# TC35678 register map
Vendor: Toshiba Electronic Devices and Storage Corporation; File version: 0.1
CPU: CM0 r0p0, little endian, no MPU, no FPU, 4 interrupt priority bits
Registers are 32-bit, read-write, no defined reset value unless marked. A register's access mark holds for its fields unless they carry their own. Offsets are from the block's base; [hi:lo] are bit positions; {n}, {i} and the like mark numbered series.

## DMAC
Base 0x40001000
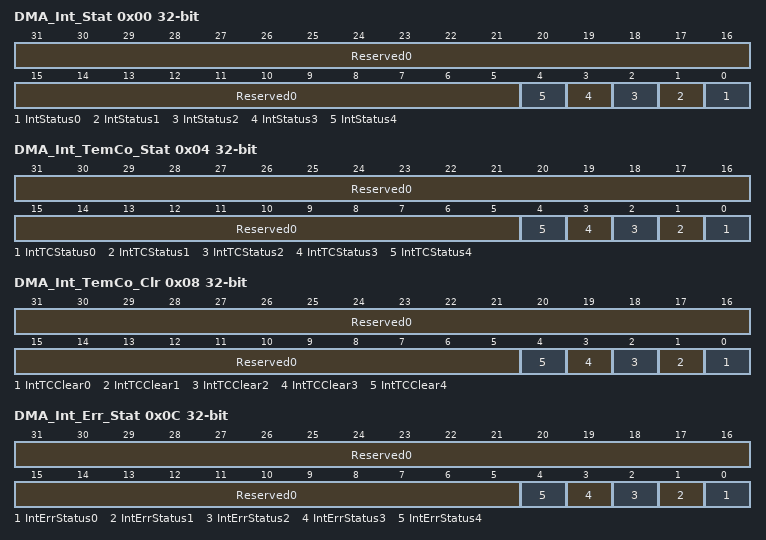
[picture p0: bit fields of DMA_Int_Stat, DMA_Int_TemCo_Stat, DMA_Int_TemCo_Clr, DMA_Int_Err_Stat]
0x00 DMA_Int_Stat ro — Interrupt Status Register
  [31:5] Reserved0 — Do not change the values.
  [n] IntStatus{n} (n=0..4) — DMAC ch{n} interrupt status. 0: No interrupt 1: Interrupt asserted. Both DMA error and DMA done assert this bit.
0x04 DMA_Int_TemCo_Stat ro — Interrupt Terminal Count Status Register
  [31:5] Reserved0 — Do not change the values.
  [n] IntTCStatus{n} (n=0..4) — DMAC ch{n} interrupt status of DMA done. 0: No interrupt 1: Interrupt asserted.
0x08 DMA_Int_TemCo_Clr — Interrupt Terminal Count Clear Register
  [31:5] Reserved0 — Do not change the values.
  [n] IntTCClear{n} ro (n=0..4) — Clear DMAC ch{n} DMA done interrupt. 0: Invalid 1: Clear
0x0C DMA_Int_Err_Stat ro — Interrupt Error Status Register
  [31:5] Reserved0 — Do not change the values.
  [n] IntErrStatus{n} (n=0..4) — DMAC ch{n} DMA error interrupt status 0: No interrupt 1: Interrupt asserted
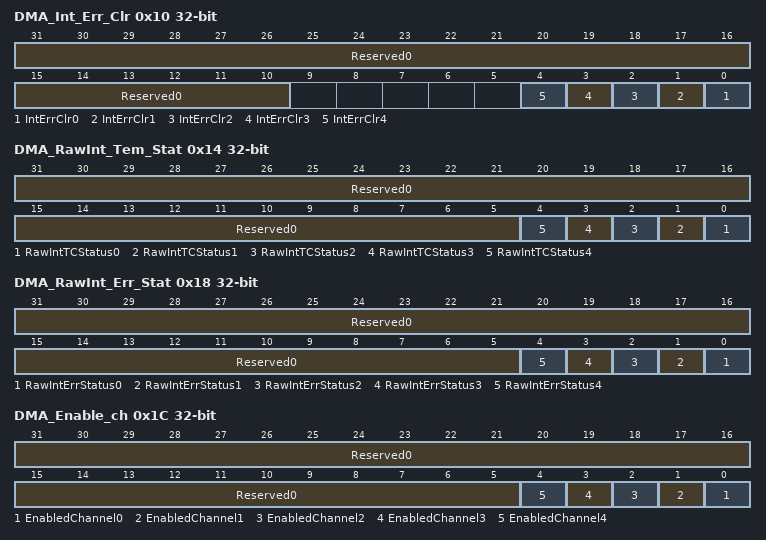
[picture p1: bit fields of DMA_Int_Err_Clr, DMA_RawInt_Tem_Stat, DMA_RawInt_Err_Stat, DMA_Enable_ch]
0x10 DMA_Int_Err_Clr — Interrupt Error Clear Register
  [31:10] Reserved0 — Do not change the values.
  [n] IntErrClr{n} (n=0..4) — Clear DMAC ch{n} DMA error interrupt 0: Invalid 1: Clear
0x14 DMA_RawInt_Tem_Stat ro — Raw Interrupt Terminal Count Status Register
  [31:5] Reserved0 — Do not change the values.
  [n] RawIntTCStatus{n} (n=0..4) — Unmasked DMAC ch{n} DMA done interrupt status 0: No interrupt 1: Interrupt asserted
0x18 DMA_RawInt_Err_Stat ro — Raw Interrupt Error Status Register
  [31:5] Reserved0 — Do not change the values.
  [n] RawIntErrStatus{n} (n=0..4) — Unmasked DMAC ch{n} DMA error interrupt status 0: No interrupt 1: Interrupt asserted
0x1C DMA_Enable_ch ro — Enabled Channel Register
  [31:5] Reserved0 — Do not change the values.
  [n] EnabledChannel{n} (n=0..4) — Enable/Disable DMAC ch{n} 0: Disable 1: Enable
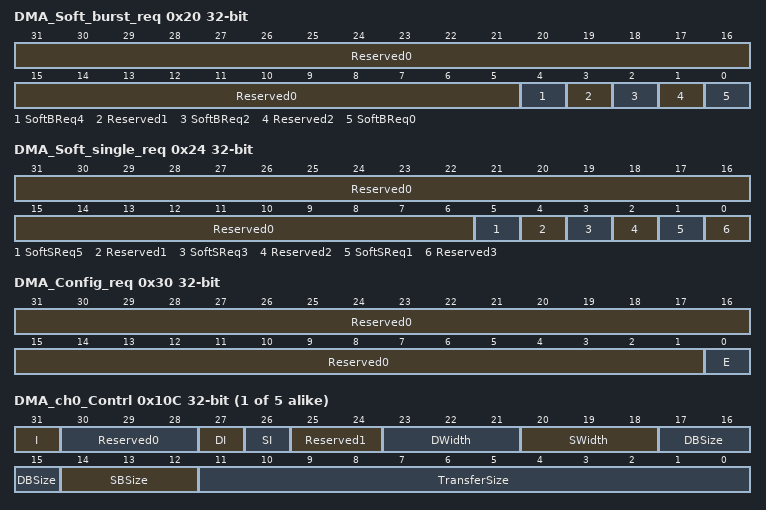
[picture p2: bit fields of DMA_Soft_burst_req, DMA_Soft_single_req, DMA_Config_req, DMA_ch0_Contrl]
0x20 DMA_Soft_burst_req — Software Burtst Request Register
  [31:5] Reserved0 — Do not change the values.
  [4] SoftBReq4 — Set DMA burst request for peripheral number 4 0: Invalid request 1: Occur request
  [3] Reserved1 — Do not change the values.
  [2] SoftBReq2 — Set DMA burst request for peripheral number 2 0: Invalid request 1: Occur request
  [1] Reserved2 — Do not change the values.
  [0] SoftBReq0 — Set DMA burst request for peripheral number 0 0: Invalid request 1: Occur request
0x24 DMA_Soft_single_req — Software Single Request Register
  [31:6] Reserved0 — Do not change the values.
  [5] SoftSReq5 — Set DMA single request for peripheral number 5 0: Invalid request 1: Occur request
  [4] Reserved1 — Do not change the values.
  [3] SoftSReq3 — Set DMA single request for peripheral number 3 0: Invalid request 1: Occur request
  [2] Reserved2 — Do not change the values.
  [1] SoftSReq1 — Set DMA single request for peripheral number 1 0: Invalid request 1: Occur request
  [0] Reserved3 — Do not change the values.
0x30 DMA_Config_req — Configuration Register
  [31:1] Reserved0 — Do not change the values.
  [0] E — Control DMA circuit 0: Halt 1: Active Set 1 to read/write DMAC registers.
{0x100+0x20*i} DMA_ch{i}_Source (i=0..4) — Channel{i} Source Address Register
  [31:0] SrcAddr — Set DMA source address Please set this value when channel{i} is disabled on DMA_ch{i}_Config register. Do not update this value while data are transferred by DMA. This address shall be 4-Byte aligned.
{0x104+0x20*i} DMA_ch{i}_Dest (i=0..4) — Channel{i} Destination Address Register
  [31:0] DestAddr — Set DMA destination address Please set this value when channel{i} is disabled on DMA_ch{i}_Config register. Do not update this value while data are transferred by DMA. This address shall be 4-Byte aligned.
{0x108+0x20*i} DMA_ch{i}_Link (i=0..4) — Channel{i} Linked ListItem Register
  [31:0] LLI — Set start address of next transfer information Please set a value of 0xFFFFFFF0 or less. When 0 is set, DMA channel will be disabled after the current DMA transfer completes. Set this register to use scatter/gather function. Scatter/gather is a function to execute DMA repeatedly according to informations which are pre-set on RAM. This address shall be 4-Byte aligned.
{0x10C+0x20*i} DMA_ch{i}_Contrl (i=0..4) — Channel{i} Control Register
  [31] I — Set interrupt enable of Terminal Count 0: Disable 1: Enable
  [30:28] Reserved0 — Do not change the values.
  [27] DI — Set increment config of destination address 0: Do not increment (The address is fixed) 1: Increment Increment timming changes according to DWidth. Each Increment timming is as follows: Bit width is 8bit: Increment every 1Byte Bit width is 16bit: Increment every 2Byte Bit width is 32bit: Increment every 4Byte
  [26] SI — Set increment config of source address 0: Do not increment (The address is fixed) 1: Increment Increment timming is the same as DI.
  [25:24] Reserved1 — Do not change the values.
  [23:21] DWidth — Set destination bit width 000: 8bit (Byte) 001: 16bit (Half word) 010: 32bit (Word) Other: Reserved
  [20:18] SWidth — Set source bit width Same as DWidth
  [17:15] DBSize — Set destination burst size 000: 1 beat 001: 4 beat 010: 8 beat 011: 16 beat 100: 32 beat 101: 64 beat 110: 128 beat 111: 256 beat
  [14:12] SBSize — Set source burst size Same as DBSize
  [11:0] TransferSize — Set the number of transfers This value is decremented on every DMA transfer. Read this value to know the number of left transfers. When DMA_ch_Config register [0] is enabled, this value can be read. The number of transfers is in unit of source bit width. Source bit width is 8bit: Set this register in unit of Byte. Source bit width is 16bit: Set this register in unit of Half word Source bit width is 32bit: Set this register in unit of Word Attention: If source bit width is smaller than destination bit width, you should be careful to set this. The following condition shall be satisfied: Source bit width * TransferSize = Destinetion bit width * N (N: integer)
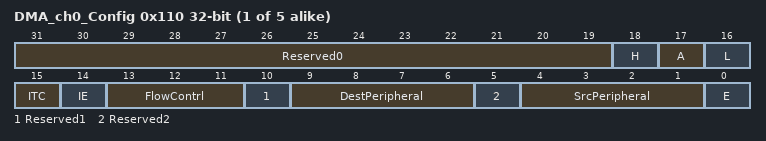
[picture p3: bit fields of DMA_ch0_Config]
{0x110+0x20*i} DMA_ch{i}_Config (i=0..4) — Channel{i} Configuration Register
  [31:19] Reserved0 — Alywas set 0.
  [18] H — Halt DMA 0: No halt 1: Halt(Ignore DMA request)
  [17] A — Check FIFO data of channel0 0: No data in FIFO 1: Data exists in FIFO
  [16] L — Set bus lock transfer config 0: Forbid bus lock transfer 1: Allow bus lock transfer If bus lock transfer is allowed, specified burst size is transferred without releassing the bus.
  [15] ITC — DMA done interrupt enable 0: enable the interrupt 1: disable the interrupt
  [14] IE — DMA error interrupt enable. 0: enable the interrupt 1: disable the interrupt
  [13:11] FlowContrl — Transfer mode config. 000: Memory to Memory 001: Memory to Pripheral 010: Peripheral to Memory 011: Peripheral to Peripheral Other: Reserved Attention: If Memory to Memory is chosen, the transfer can be started to write 1 to E.
  [10] Reserved1 — Always set 0.
  [9:6] DestPeripheral — DMA destination peripheral number Min: 0000 Max: 1111 If the destination is Memory, this value is ignored.
  [5] Reserved2 — Always set 0.
  [4:1] SrcPeripheral — DMA source peripheral config register Min: 0000 Max: 1111 If the source is Memory, this value is ignored.
  [0] E — Set channel enable 0: Disable 1: Enable After you set up the all DMA settings, set 1 to this register. When this value set disable during transfer, FIFO data of channel0 is erased. If you want to restart the transfer, please initialize all config of channel0 and restart the DMA. If you want to stop the transfer temporarily, please perform the following sequence: (1)Set 1 to register H, then DMA requirement stop. (2)Poll FIFO data until register A becomes 0 (FIFO if empty). (3)Set 0(disable) to this register, and write 0(disable) to register E.
